# NUC122_v1 register map
File version: 1.0
Registers are 32-bit, read-write, reset 0x0 unless marked. A register's access mark holds for its fields unless they carry their own. Offsets are from the block's base; [hi:lo] are bit positions; {n}, {i} and the like mark numbered series.

## USB — USB Register Map
Base 0x40060000
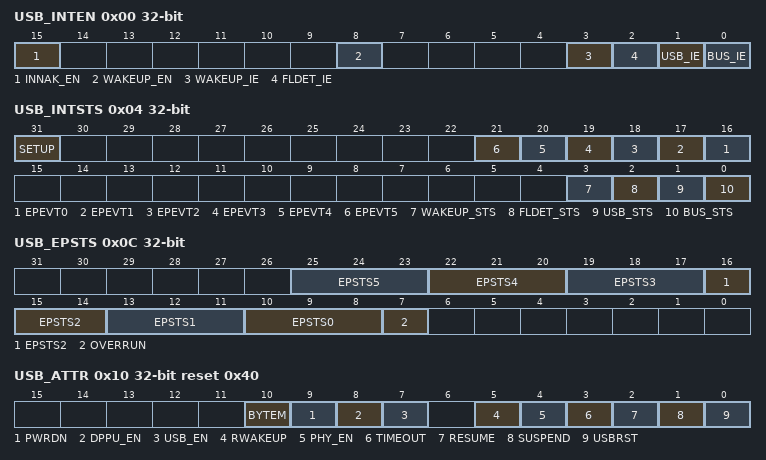
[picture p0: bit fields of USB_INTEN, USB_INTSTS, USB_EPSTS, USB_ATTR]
0x00 USB_INTEN — USB Interrupt Enable Register
  [15] INNAK_EN — Active NAK Function and its Status in IN Token
    0=The NAK status doesn't be updated into the endpoint status register when it was set to 0. It also disable the interrupt event when device responds NAK after receiving IN token; 1=The NAK status is updated into the endpoint status register, USB_EPSTS, when it is set to 1 and there is NAK response in IN token. It also enable the interrupt event when the device responds NAK after receiving IN token
  [8] WAKEUP_EN — Wake-Up Function Enable
    0=Disable USB wake-up function; 1=Enable USB wake-up function
  [3] WAKEUP_IE — USB Wake-Up Interrupt Enable
    0=Disable USB wake-up Interrupt; 1=Enable USB wake-up Interrupt
  [2] FLDET_IE — Floating Detected Interrupt Enable
    0=Disable Floating detect Interrupt; 1=Enable Floating detect Interrupt
  [1] USB_IE — USB Event Interrupt Enable
    0=Disable USB event interrupt; 1=Enable USB event interrupt
  [0] BUS_IE — Bus Event Interrupt Enable
    0=Disable BUS event interrupt; 1=Enable BUS event interrupt
0x04 USB_INTSTS — USB Interrupt Event Status Register
  [31] SETUP — Setup Event Status
    0=No Setup event; 1=Setup event occurred, cleared by write 1 to USB_INTSTS[31]
  [n+16] EPEVT{n} (n=0..5) — Endpoint {n}'s USB Event Status
    0=No event occurred in endpoint {n}; 1=USB event occurred on Endpoint {n}, check USB_EPSTS[{3n+10}:{3n+8}] to know which kind of USB event was occurred, cleared by write 1 to USB_INTSTS[{n+16}] or USB_INTSTS[1]
  [3] WAKEUP_STS — Wake-Up Interrupt Status
    0=No wake-up event is occurred; 1=Wake-up event occurred, cleared by write 1 to USB_INTSTS[3]
  [2] FLDET_STS — Floating Detected Interrupt Status
    0=There is not attached/detached event in the USB; 1=There is attached/detached event in the USB bus and it is cleared by write 1 to USB_INTSTS[2]
  [1] USB_STS — USB Event Interrupt Status. The USB event includes the Setup Token, IN Token, OUT ACK, ISO IN, or ISO OUT events in the bus.
    0=No any USB event is occurred; 1=USB event occurred, check EPSTS0~5[2:0] to know which kind of USB event was occurred, cleared by write 1 to USB_INTSTS[1] or EPSTS0~5 and SETUP (USB_INTSTS[31])
  [0] BUS_STS — BUS Interrupt Status. The BUS event means that there is one of the suspense or the resume function in the bus.
    0=No any BUS event is occurred; 1=Bus event occurred; check USB_ATTR[3:0] to know which kind of bus event was occurred, cleared by write 1 to USB_INTSTS[0]
0x08 USB_FADDR — USB Device Function Address Register
  [6:0] FADDR — USB device's Function Address
0x0C USB_EPSTS ro — USB Endpoint Status Register
  [3n+10:3n+8] EPSTS{n} (n=0..5) — Endpoint {n} Bus Status. These bits are used to indicate the current status of this endpoint
    0=In ACK; 1=In NAK; 2=Out Packet Data0 ACK; 3=Setup ACK; 6=Out Packet Data1 ACK; 7=Isochronous transfer end
  [7] OVERRUN — Overrun. It indicates that the received data is over the maximum payload number or not.
    0=No overrun; 1=It indicates that the Out Data more than the Max Payload in MXPLD register or the Setup Data more than 8 Bytes
0x10 USB_ATTR reset 0x40 — USB Bus Status and Attribution Register
  [10] BYTEM — CPU access USB SRAM Size Mode Selection
    0=Word Mode: The size of the transfer from CPU to USB SRAM can be Word only; 1=Byte Mode: The size of the transfer from CPU to USB SRAM can be Byte only
  [9] PWRDN — Power Down PHY Transceiver (low active)
    0=power down related circuit of PHY transceiver; 1=Turn-on related circuit of PHY transceiver
  [8] DPPU_EN — Pull-up Resistor on USB_DP Enable
    0=Disable the pull-up resistor in USB_DP bus; 1=The pull-up resistor in USB_DP bus active
  [7] USB_EN — USB Controller Enable
    0=Disable USB Controller; 1=Enable USB Controller
  [5] RWAKEUP — Remote Wake-Up
    0=Release the USB bus from K state; 1=Force USB bus to K (USB_DP low, USB_DM: high) state, used for remote wake-up
  [4] PHY_EN — PHY Transceiver Function Enable
    0=Disable PHY transceiver function; 1=Enable PHY transceiver function
  [3] TIMEOUT — Time-Out Status. It is a read only bit.
    0=No time-out; 1=Bus no any response more than 18 bits time
  [2] RESUME — Resume Status. It is a read only bit.
    0=No bus resume; 1=Resume from suspend
  [1] SUSPEND — Suspend Status. It is a read only bit.
    0=Bus no suspend; 1=Bus idle more than 3 ms, either cable is plugged off or host is sleeping
  [0] USBRST — USB Reset Status. It is a read only bit.
    0=Bus no reset; 1=Bus reset when SE0 (single-ended 0) more than 2.5us
0x14 USB_FLDET ro — USB Floating Detected Register
  [0] FLDET — Device Floating Detected
    0=The controller didn't attached into the USB host; 1=When the controller is attached into the BUS, this bit will be set as 1
0x18 USB_BUFSEG — Setup Token Buffer Segmentation Register
  [8:3] BUFSEG — It is used to indicate the offset address for the Setup token with the USB SRAM starting address. The effective starting address is. USB_SRAM address + { BUFSEG[8:3], 3'b000} Note: It is used for Setup token only.
{0x20+0x10*i} USB_BUFSEG{i} (i=0..5) — Endpoint {i} Buffer Segmentation Register
  [8:3] BUFSEGx — It is used to indicate the offset address for each endpoint with the USB SRAM starting address. The effective starting address of the endpoint is. USB_SRAM address + {BUFSEG[8:3], 3'b000} Refer to section 5.4.4.7 for the endpoint SRAM structure and its description.
{0x24+0x10*i} USB_MXPLD{i} (i=0..5) — Endpoint {i} Maximal Payload Register
  [8:0] MXPLD — Maximal Payload. It is used to define the data length which is transmitted to host (IN token) or the actual data length which is received from the host (OUT token). It also used to indicate that the endpoint is ready to be transmitted in IN token or received in OUT token. (1). When the register is written by CPU, For IN token, the value of MXPLD is used to define the data length to be transmitted and indicate the data buffer is ready. For OUT token, it means that the controller is ready to receive data from the host and the value of MXPLD is the maximal data length comes from host. (2). When the register is read by CPU, For IN token, the value of MXPLD is indicated the data length be transmitted to host. For OUT token, the value of MXPLD is indicated the actual data length receiving from host. Note that once MXPLD is written, the data packets will be transmitted/received immediately after IN/OUT token arrived.
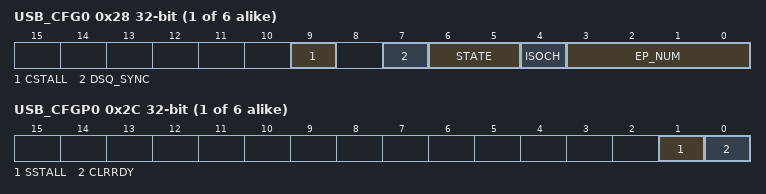
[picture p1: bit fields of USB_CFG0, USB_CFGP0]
{0x28+0x10*i} USB_CFG{i} (i=0..5) — Endpoint {i} Configuration Register
  [9] CSTALL — Clear STALL Response
    0=Disable the device to clear the STALL handshake in setup stage; 1=Clear the device to response STALL handshake in setup stage
  [7] DSQ_SYNC — Data Sequence Synchronization. It is used to specify the DATA0 or DATA1 PID in the following IN token transaction. H/W will toggle automatically in IN token base on the bit.
    0=DATA0 PID; 1=DATA1 PID
  [6:5] STATE — Endpoint STATE
    0=Endpoint is disabled; 1=Out endpoint; 2=IN endpoint; 3=Undefined
  [4] ISOCH — Isochronous Endpoint. This bit is used to set the endpoint as Isochronous endpoint, no handshake.
    0=No Isochronous endpoint; 1=Isochronous endpoint
  [3:0] EP_NUM — Endpoint Number. These bits are used to define the endpoint number of the current endpoint
{0x2C+0x10*i} USB_CFGP{i} (i=0..5) — Endpoint {i} Set Stall and Clear In/Out Ready Control Register
  [1] SSTALL — Set STALL
    0=Disable the device to response STALL; 1=Set the device to respond STALL automatically
  [0] CLRRDY — Clear Ready. When the MXPLD register is set by user, it means that the endpoint is ready to transmit or receive data. If the user wants to turn off this transaction before the transaction start, users can set this bit to 1 to turn it off and it is auto clear to 0. For IN token, write '1' is used to clear the IN token had ready to transmit the data to USB. For OUT token, write '1' is used to clear the OUT token had ready to receive the data from USB. This bit is write 1 only and it is always 0 when it was read back.
0x90 USB_DRVSE0 reset 0x1 — USB Drive SE0 Control Register
  [0] DRVSE0 — Drive Single Ended Zero in USB Bus. The Single Ended Zero (SE0) is when both lines (USB_DP and USB_DM) are being pulled low.
    0=None; 1=Force USB PHY transceiver to drive SE0
